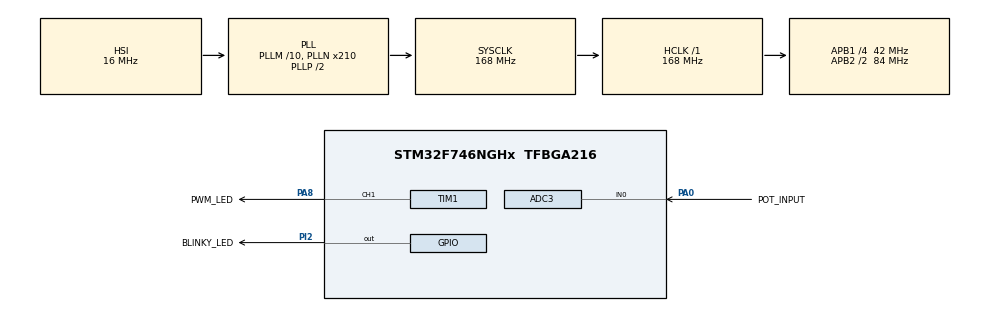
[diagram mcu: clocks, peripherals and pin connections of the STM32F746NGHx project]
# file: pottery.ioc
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ADC3.Channel-0\#ChannelRegularConversion=ADC_CHANNEL_0
ADC3.NbrOfConversionFlag=1
ADC3.Rank-0\#ChannelRegularConversion=1
ADC3.SamplingTime-0\#ChannelRegularConversion=ADC_SAMPLETIME_3CYCLES
Mcu.Family=STM32F7
Mcu.Name=STM32F746NGHx
Mcu.Package=TFBGA216
NVIC.PriorityGroup=NVIC_PRIORITYGROUP_4
NVIC.TIM2_IRQn=true\:1\:0\:true\:false\:true\:true\:true
NVIC.TIM8_TRG_COM_TIM14_IRQn=true\:0\:0\:false\:false\:true\:false\:true
NVIC.TimeBase=TIM8_TRG_COM_TIM14_IRQn
NVIC.TimeBaseIP=TIM14
PA0/WKUP.GPIO_Label=POT_INPUT
PA0/WKUP.Signal=ADCx_IN0
PA13.Mode=Serial_Wire
PA13.Signal=SYS_JTMS-SWDIO
PA14.Mode=Serial_Wire
PA14.Signal=SYS_JTCK-SWCLK
PA8.GPIO_Label=PWM_LED
PA8.Signal=S_TIM1_CH1
PC14/OSC32_IN.Mode=LSE-External-Clock-Source
PC14/OSC32_IN.Signal=RCC_OSC32_IN
PC15/OSC32_OUT.Mode=LSE-External-Clock-Source
PC15/OSC32_OUT.Signal=RCC_OSC32_OUT
PH0/OSC_IN.Mode=HSE-External-Oscillator
PH0/OSC_IN.Signal=RCC_OSC_IN
PH1/OSC_OUT.Mode=HSE-External-Oscillator
PH1/OSC_OUT.Signal=RCC_OSC_OUT
PI2.GPIO_Label=BLINKY_LED
PI2.Signal=GPIO_Output
ProjectManager.HeapSize=0x200
ProjectManager.StackSize=0x400
ProjectManager.TargetToolchain=STM32CubeIDE
RCC.AHBFreq_Value=168000000
RCC.APB1CLKDivider=RCC_HCLK_DIV4
RCC.APB1Freq_Value=42000000
RCC.APB1TimFreq_Value=84000000
RCC.APB2CLKDivider=RCC_HCLK_DIV2
RCC.APB2Freq_Value=84000000
RCC.APB2TimFreq_Value=168000000
RCC.CortexFreq_Value=168000000
RCC.HCLKFreq_Value=168000000
RCC.HSE_VALUE=25000000
RCC.HSI_VALUE=16000000
RCC.LSE_VALUE=32768
RCC.PLLM=10
RCC.PLLN=210
RCC.PLLSourceVirtual=RCC_PLLSOURCE_HSI
RCC.SYSCLKFreq_VALUE=168000000
RCC.SYSCLKSource=RCC_SYSCLKSOURCE_PLLCLK
RCC.USBFreq_Value=168000000
RCC.VCOOutputFreq_Value=336000000
SH.ADCx_IN0.0=ADC3_IN0,IN0
SH.S_TIM1_CH1.0=TIM1_CH1,PWM Generation1 CH1
TIM1.Channel-PWM\ Generation1\ CH1=TIM_CHANNEL_1
TIM1.Period=5850-1
TIM1.Prescaler=168-1
TIM2.Period=82030-1
TIM2.Prescaler=512-1
VP_SYS_VS_tim14.Mode=TIM14
VP_TIM2_VS_ClockSourceINT.Mode=Internal
board=STM32F746G-DISCO

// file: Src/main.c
/* USER CODE BEGIN Header */
/**
  ******************************************************************************
  * @file           : main.c
  * @brief          : Main program body
  ******************************************************************************
  * @attention
  *
  * <h2><center>&copy; Copyright (c) 2019 STMicroelectronics.
  * All rights reserved.</center></h2>
  *
  * This software component is licensed by ST under BSD 3-Clause license,
  * the "License"; You may not use this file except in compliance with the
  * License. You may obtain a copy of the License at:
  *                        opensource.org/licenses/BSD-3-Clause
  *
  ******************************************************************************
  */
/* USER CODE END Header */

#include "main.h"

ADC_HandleTypeDef hadc3;

TIM_HandleTypeDef htim1;
TIM_HandleTypeDef htim2;

/* USER CODE BEGIN PV */

uint16_t adc_duty_cycle = 0;
uint16_t adc_frequency = 0;

/* USER CODE END PV */

void SystemClock_Config(void);
static void MX_GPIO_Init(void);
static void MX_ADC3_Init(void);
static void MX_TIM1_Init(void);
static void MX_TIM2_Init(void);

int main(void)
{

  /* MCU Configuration--------------------------------------------------------*/

  /* Reset of all peripherals, Initializes the Flash interface and the Systick. */
  HAL_Init();

  /* Configure the system clock */
  SystemClock_Config();

  /* Initialize all configured peripherals */
  MX_GPIO_Init();
  MX_ADC3_Init();
  MX_TIM1_Init();
  MX_TIM2_Init();
  /* USER CODE BEGIN 2 */

  HAL_TIM_PWM_Start(&htim1, TIM_CHANNEL_1);
  HAL_TIM_Base_Start_IT(&htim2);

  /* USER CODE END 2 */

  /* Infinite loop */
  /* USER CODE BEGIN WHILE */
  while (1)
  {

    //HAL_Delay(4);
       // printf("Hello world\r\n");
        HAL_ADC_Start(&hadc3);
        if (HAL_ADC_PollForConversion(&hadc3, 10) == HAL_OK) {
           adc_duty_cycle = HAL_ADC_GetValue(&hadc3);
           adc_frequency= HAL_ADC_GetValue(&hadc3);

          TIM1 -> CCR1 = 100 + adc_duty_cycle;
          TIM2 -> PSC = adc_frequency / 4;

                //  HAL_Delay(4);

          //char asd[50];
          //sprintf(asd, "ADC value: %d\r\n", adc_value);
          //HAL_UART_Transmit(&huart1, asd, strlen(asd), 0xFFFF);
          //printf("ADC value: %d.\n", adc_value);
        }
    /* USER CODE END WHILE */

  }
}

void SystemClock_Config(void)
{
  RCC_OscInitTypeDef RCC_OscInitStruct = {0};
  RCC_ClkInitTypeDef RCC_ClkInitStruct = {0};

  /** Configure the main internal regulator output voltage
  */
  __HAL_RCC_PWR_CLK_ENABLE();
  __HAL_PWR_VOLTAGESCALING_CONFIG(PWR_REGULATOR_VOLTAGE_SCALE2);
  /** Initializes the CPU, AHB and APB busses clocks
  */
  RCC_OscInitStruct.OscillatorType = RCC_OSCILLATORTYPE_HSI;
  RCC_OscInitStruct.HSIState = RCC_HSI_ON;
  RCC_OscInitStruct.HSICalibrationValue = RCC_HSICALIBRATION_DEFAULT;
  RCC_OscInitStruct.PLL.PLLState = RCC_PLL_ON;
  RCC_OscInitStruct.PLL.PLLSource = RCC_PLLSOURCE_HSI;
  RCC_OscInitStruct.PLL.PLLM = 10;
  RCC_OscInitStruct.PLL.PLLN = 210;
  RCC_OscInitStruct.PLL.PLLP = RCC_PLLP_DIV2;
  RCC_OscInitStruct.PLL.PLLQ = 2;
  if (HAL_RCC_OscConfig(&RCC_OscInitStruct) != HAL_OK)
  {
    Error_Handler();
  }
  /** Initializes the CPU, AHB and APB busses clocks
  */
  RCC_ClkInitStruct.ClockType = RCC_CLOCKTYPE_HCLK|RCC_CLOCKTYPE_SYSCLK
                              |RCC_CLOCKTYPE_PCLK1|RCC_CLOCKTYPE_PCLK2;
  RCC_ClkInitStruct.SYSCLKSource = RCC_SYSCLKSOURCE_PLLCLK;
  RCC_ClkInitStruct.AHBCLKDivider = RCC_SYSCLK_DIV1;
  RCC_ClkInitStruct.APB1CLKDivider = RCC_HCLK_DIV4;
  RCC_ClkInitStruct.APB2CLKDivider = RCC_HCLK_DIV2;

  if (HAL_RCC_ClockConfig(&RCC_ClkInitStruct, FLASH_LATENCY_5) != HAL_OK)
  {
    Error_Handler();
  }
}

static void MX_ADC3_Init(void)
{

  ADC_ChannelConfTypeDef sConfig = {0};

  /** Configure the global features of the ADC (Clock, Resolution, Data Alignment and number of conversion)
  */
  hadc3.Instance = ADC3;
  hadc3.Init.ClockPrescaler = ADC_CLOCK_SYNC_PCLK_DIV4;
  hadc3.Init.Resolution = ADC_RESOLUTION_12B;
  hadc3.Init.ScanConvMode = ADC_SCAN_DISABLE;
  hadc3.Init.ContinuousConvMode = DISABLE;
  hadc3.Init.DiscontinuousConvMode = DISABLE;
  hadc3.Init.ExternalTrigConvEdge = ADC_EXTERNALTRIGCONVEDGE_NONE;
  hadc3.Init.ExternalTrigConv = ADC_SOFTWARE_START;
  hadc3.Init.DataAlign = ADC_DATAALIGN_RIGHT;
  hadc3.Init.NbrOfConversion = 1;
  hadc3.Init.DMAContinuousRequests = DISABLE;
  hadc3.Init.EOCSelection = ADC_EOC_SINGLE_CONV;
  if (HAL_ADC_Init(&hadc3) != HAL_OK)
  {
    Error_Handler();
  }
  /** Configure for the selected ADC regular channel its corresponding rank in the sequencer and its sample time.
  */
  sConfig.Channel = ADC_CHANNEL_0;
  sConfig.Rank = ADC_REGULAR_RANK_1;
  sConfig.SamplingTime = ADC_SAMPLETIME_3CYCLES;
  if (HAL_ADC_ConfigChannel(&hadc3, &sConfig) != HAL_OK)
  {
    Error_Handler();
  }

}

static void MX_TIM1_Init(void)
{

  TIM_MasterConfigTypeDef sMasterConfig = {0};
  TIM_OC_InitTypeDef sConfigOC = {0};
  TIM_BreakDeadTimeConfigTypeDef sBreakDeadTimeConfig = {0};

  htim1.Instance = TIM1;
  htim1.Init.Prescaler = 168-1;
  htim1.Init.CounterMode = TIM_COUNTERMODE_UP;
  htim1.Init.Period = 5850-1;
  htim1.Init.ClockDivision = TIM_CLOCKDIVISION_DIV1;
  htim1.Init.RepetitionCounter = 0;
  htim1.Init.AutoReloadPreload = TIM_AUTORELOAD_PRELOAD_DISABLE;
  if (HAL_TIM_PWM_Init(&htim1) != HAL_OK)
  {
    Error_Handler();
  }
  sMasterConfig.MasterOutputTrigger = TIM_TRGO_RESET;
  sMasterConfig.MasterOutputTrigger2 = TIM_TRGO2_RESET;
  sMasterConfig.MasterSlaveMode = TIM_MASTERSLAVEMODE_DISABLE;
  if (HAL_TIMEx_MasterConfigSynchronization(&htim1, &sMasterConfig) != HAL_OK)
  {
    Error_Handler();
  }
  sConfigOC.OCMode = TIM_OCMODE_PWM1;
  sConfigOC.Pulse = 0;
  sConfigOC.OCPolarity = TIM_OCPOLARITY_HIGH;
  sConfigOC.OCNPolarity = TIM_OCNPOLARITY_HIGH;
  sConfigOC.OCFastMode = TIM_OCFAST_DISABLE;
  sConfigOC.OCIdleState = TIM_OCIDLESTATE_RESET;
  sConfigOC.OCNIdleState = TIM_OCNIDLESTATE_RESET;
  if (HAL_TIM_PWM_ConfigChannel(&htim1, &sConfigOC, TIM_CHANNEL_1) != HAL_OK)
  {
    Error_Handler();
  }
  sBreakDeadTimeConfig.OffStateRunMode = TIM_OSSR_DISABLE;
  sBreakDeadTimeConfig.OffStateIDLEMode = TIM_OSSI_DISABLE;
  sBreakDeadTimeConfig.LockLevel = TIM_LOCKLEVEL_OFF;
  sBreakDeadTimeConfig.DeadTime = 0;
  sBreakDeadTimeConfig.BreakState = TIM_BREAK_DISABLE;
  sBreakDeadTimeConfig.BreakPolarity = TIM_BREAKPOLARITY_HIGH;
  sBreakDeadTimeConfig.BreakFilter = 0;
  sBreakDeadTimeConfig.Break2State = TIM_BREAK2_DISABLE;
  sBreakDeadTimeConfig.Break2Polarity = TIM_BREAK2POLARITY_HIGH;
  sBreakDeadTimeConfig.Break2Filter = 0;
  sBreakDeadTimeConfig.AutomaticOutput = TIM_AUTOMATICOUTPUT_DISABLE;
  if (HAL_TIMEx_ConfigBreakDeadTime(&htim1, &sBreakDeadTimeConfig) != HAL_OK)
  {
    Error_Handler();
  }
  HAL_TIM_MspPostInit(&htim1);

}

static void MX_TIM2_Init(void)
{

  TIM_ClockConfigTypeDef sClockSourceConfig = {0};
  TIM_MasterConfigTypeDef sMasterConfig = {0};

  htim2.Instance = TIM2;
  htim2.Init.Prescaler = 512-1;
  htim2.Init.CounterMode = TIM_COUNTERMODE_UP;
  htim2.Init.Period = 82030-1;
  htim2.Init.ClockDivision = TIM_CLOCKDIVISION_DIV1;
  htim2.Init.AutoReloadPreload = TIM_AUTORELOAD_PRELOAD_DISABLE;
  if (HAL_TIM_Base_Init(&htim2) != HAL_OK)
  {
    Error_Handler();
  }
  sClockSourceConfig.ClockSource = TIM_CLOCKSOURCE_INTERNAL;
  if (HAL_TIM_ConfigClockSource(&htim2, &sClockSourceConfig) != HAL_OK)
  {
    Error_Handler();
  }
  sMasterConfig.MasterOutputTrigger = TIM_TRGO_RESET;
  sMasterConfig.MasterSlaveMode = TIM_MASTERSLAVEMODE_DISABLE;
  if (HAL_TIMEx_MasterConfigSynchronization(&htim2, &sMasterConfig) != HAL_OK)
  {
    Error_Handler();
  }

}

static void MX_GPIO_Init(void)
{
  GPIO_InitTypeDef GPIO_InitStruct = {0};

  /* GPIO Ports Clock Enable */
  __HAL_RCC_GPIOA_CLK_ENABLE();
  __HAL_RCC_GPIOI_CLK_ENABLE();
  __HAL_RCC_GPIOC_CLK_ENABLE();
  __HAL_RCC_GPIOH_CLK_ENABLE();

  /*Configure GPIO pin Output Level */
  HAL_GPIO_WritePin(BLINKY_LED_GPIO_Port, BLINKY_LED_Pin, GPIO_PIN_RESET);

  /*Configure GPIO pin : BLINKY_LED_Pin */
  GPIO_InitStruct.Pin = BLINKY_LED_Pin;
  GPIO_InitStruct.Mode = GPIO_MODE_OUTPUT_PP;
  GPIO_InitStruct.Pull = GPIO_NOPULL;
  GPIO_InitStruct.Speed = GPIO_SPEED_FREQ_LOW;
  HAL_GPIO_Init(BLINKY_LED_GPIO_Port, &GPIO_InitStruct);

}

void HAL_TIM_PeriodElapsedCallback(TIM_HandleTypeDef *htim)
{
  /* USER CODE BEGIN Callback 0 */

  if (htim->Instance == TIM2){
    HAL_GPIO_TogglePin(BLINKY_LED_GPIO_Port, BLINKY_LED_Pin);
  }

  /* USER CODE END Callback 0 */
  if (htim->Instance == TIM14) {
    HAL_IncTick();
  }
}

void Error_Handler(void)
{
}

/************************ (C) COPYRIGHT STMicroelectronics *****END OF FILE****/
